# STM32G484 register map
File version: 2.1
CPU: CM4 r0p1, little endian, MPU, FPU, 4 interrupt priority bits
Registers are 32-bit, read-write, reset 0x0 unless marked. A register's access mark holds for its fields unless they carry their own. Offsets are from the block's base; [hi:lo] are bit positions; {n}, {i} and the like mark numbered series.

## RNG — Random number generator
Base 0x50060800
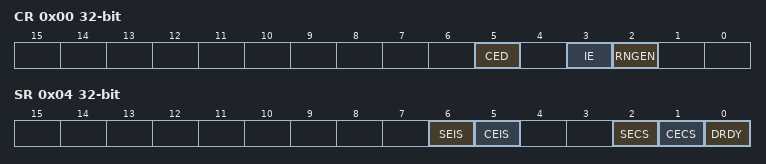
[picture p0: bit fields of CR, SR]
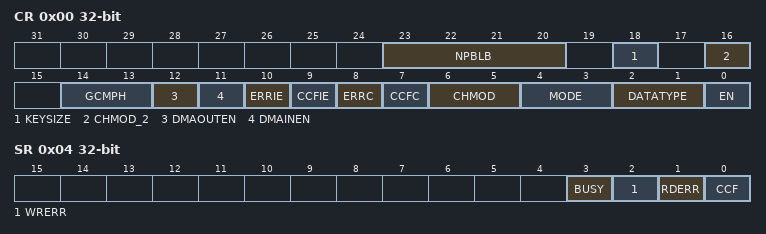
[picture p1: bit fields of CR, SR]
0x00 CR — control register
  [5] CED — Clock error detection
    0=Enabled (Clock error detection is enabled); 1=Disabled (Clock error detection is disabled)
  [3] IE — Interrupt enable
    0=Disabled (RNG interrupt is disabled); 1=Enabled (RNG interrupt is enabled)
  [2] RNGEN — Random number generator enable
    0=Disabled (Random number generator is disabled); 1=Enabled (Random number generator is enabled)
0x04 SR access per field — status register
  [6] SEIS rw write-0-clears — Seed error interrupt status
    on write: 0=Clear flag | on read: 0=No faulty sequence detected; 1=Fault (At least one faulty sequence has been detected. See **SECS** bit description for details. An interrupt is pending if IE = 1 in the RNG_CR register.)
  [5] CEIS rw write-0-clears — Clock error interrupt status
    on write: 0=Clear flag | on read: 0=Correct (The RNG clock is correct); 1=Slow (The RNG has been detected too slow An interrupt is pending if IE = 1 in the RNG_CR register)
  [2] SECS ro — Seed error current status
    0=No faulty sequence has currently been detected. If the SEIS bit is set, this means that a faulty sequence was detected and the situation has been recovered.; 1=Fault (At least one faulty sequence has been detected - see ref manual for details)
  [1] CECS ro — Clock error current status
    0=Correct (The RNG clock is correct. If the CEIS bit is set, this means that a slow clock was detected and the situation has been recovered.); 1=Slow (The RNG clock is too slow)
  [0] DRDY ro — Data ready
    0=Invalid (The RNG_DR register is not yet valid, no random data is available); 1=Valid (The RNG_DR register contains valid random data. Once the RNG_DR register has been read, this bit returns to 0 until a new random value is generated.)
0x08 DR ro — data register
  [31:0] RNDATA — Random data

## AES — Advanced encryption standard hardware accelerator
Base 0x50060000
0x00 CR — control register
  [23:20] NPBLB
  [18] KEYSIZE
    0=AES128 (128); 1=AES256 (256)
  [16] CHMOD_2
    0=CHMOD (Mode as per CHMOD (ECB, CBC, CTR, GCM)); 1=CCM (Counter with CBC-MAC (CCM) - CHMOD must be 0 (ECB))
  [14:13] GCMPH
    0=Init phase; 1=Header phase; 2=Payload phase; 3=Final Phase
  [12] DMAOUTEN — Enable DMA management of data output phase
    0=Disable DMA Output; 1=Enabled DMA Output
  [11] DMAINEN — Enable DMA management of data input phase
    0=Disable DMA Input; 1=Enable DMA Input
  [10] ERRIE — Error interrupt enable
    0=Disabled (Disable (mask) error interrupt); 1=Enabled (Enable error interrupt)
  [9] CCFIE — CCF flag interrupt enable
    0=Disabled (Disable (mask) CCF interrupt); 1=Enabled (Enable CCF interrupt)
  [8] ERRC — Error clear
    on write: 1=Clear RDERR and WRERR flags
  [7] CCFC — Computation Complete Flag Clear
    on write: 1=Clear computation complete flag
  [6:5] CHMOD — AES chaining mode
    0=ECB (Electronic codebook (ECB) / Counter with CBC-MAC (CCM) if CHMOD2 is 1); 1=CBC (Cipher-block chaining (CBC)); 2=CTR (Counter mode (CTR)); 3=GCM (Galois counter mode (GCM) and Galois message authentication code (GMAC))
  [4:3] MODE — AES operating mode
    0=Mode 1: encryption; 1=Mode 2: key derivation (or key preparation for ECB/CBC decryption); 2=Mode 3: decryption; 3=Mode 4: key derivation then single decryption
  [2:1] DATATYPE — Data type selection (for data in and data out to/from the cryptographic block)
    0=None (Word); 1=Half-word (16-bit); 2=Byte (8-bit); 3=Bit
  [0] EN — AES enable
    0=Disabled (Disable AES); 1=Enabled (Enable AES)
0x04 SR ro — status register
  [3] BUSY
    0=Idle; 1=Busy
  [2] WRERR — Write error flag
    0=NoError (Write error not detected); 1=Error (Write error detected)
  [1] RDERR — Read error flag
    0=NoError (Read error not detected); 1=Error (Read error detected)
  [0] CCF — Computation complete flag
    0=Complete (Computation complete); 1=NotComplete (Computation not complete)
0x08 DINR — data input register
  [31:0] DIN — Data Input Register
0x0C DOUTR ro — data output register
  [31:0] DOUT — Data output register
0x10 KEYR0 — key register 0
  [31:0] KEY — Data Output Register (LSB key [31:0])
0x14 KEYR1 — key register 1
  [31:0] KEY — AES key register (key [63:32])
0x18 KEYR2 — key register 2
  [31:0] KEY — AES key register (key [95:64])
0x1C KEYR3 — key register 3
  [31:0] KEY — AES key register (MSB key [127:96])
0x20 IVR0 — initialization vector register 0
  [31:0] IVI — initialization vector register (LSB IVR [31:0])
0x24 IVR1 — initialization vector register 1
  [31:0] IVI — Initialization Vector Register (IVR [63:32])
0x28 IVR2 — initialization vector register 2
  [31:0] IVI — Initialization Vector Register (IVR [95:64])
0x2C IVR3 — initialization vector register 3
  [31:0] IVI — Initialization Vector Register (MSB IVR [127:96])
{0x20+4i} KEYR{i} (i=4..7) — key register {i}
  [31:0] KEY — AES key
{0x40+4i} SUSP{i}R (i=0..7) — suspend registers
  [31:0] SUSP — AES suspend
